# MAX32550 register map
Vendor: Maxim Integrated; File version: 1.0
Registers are 32-bit, read-write, reset 0x0 unless marked. A register's access mark holds for its fields unless they carry their own. Offsets are from the block's base; [hi:lo] are bit positions; {n}, {i} and the like mark numbered series.

## UART0 — UART0 (Serial Port 0)
Base 0x40020000; register names take the prefix UART0_
Same registers: UART1 0x40021000 (register names take the prefix UART1_)
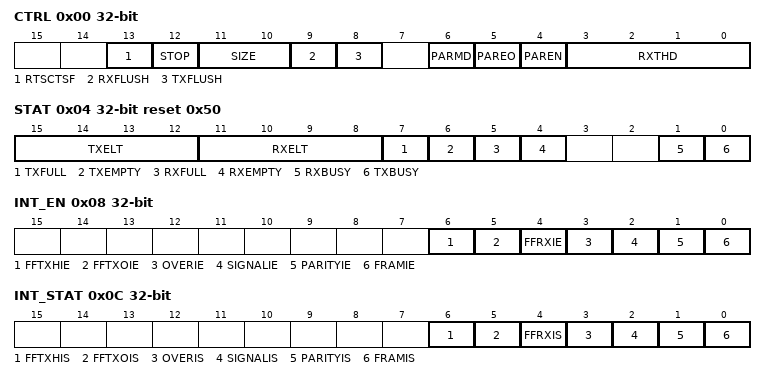
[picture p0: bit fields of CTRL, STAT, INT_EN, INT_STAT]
0x00 CTRL — UART Control Register
  [13] RTSCTSF — Enables/disables hardware flow control.
    0=disable; 1=enable
  [12] STOP — Selects the number of stop bits that will be generated.
    0=1 stop bit; 1=1.5 stop bits (for 5 bit mode) or 2 stop bits (for 6/7/8 bit mode)
  [11:10] SIZE — Selects UART character size.
    {v}=bits{v+5} (v=0..3)
  [9] RXFLUSH — Flushes the RX FIFO buffer.
    0=complete (No operation/complete); 1=Start operation
  [8] TXFLUSH — Flushes the TX FIFO buffer.
    0=complete (No operation/complete); 1=Start operation
  [6] PARMD — Selects parity based on 1s or 0s count (when PAREN=1).
    0=count1s (Parity calculation is based on number of 1s in frame.); 1=count0s (Parity calculation is based on number of 0s in frame.)
  [5] PAREO — Selects odd or even parity (when PAREN=1).
    0=even; 1=odd
  [4] PAREN — Enables/disables generation and testing of parity bit.
    0=disable; 1=enable
  [3:0] RXTHD — Number of bytes that must be loaded into the receive FIFO before the FFRXIS interrupt will be triggered.
    other=ignored; 1=bytes1 (Interrupt will be triggered when the number of bytes in the RX FIFO reaches 1 byte or higher.); {v}=bytes{v} (Interrupt will be triggered when the number of bytes in the RX FIFO reaches {v} bytes or higher.) (v=2..8)
0x04 STAT ro reset 0x50 — UART Status Register
  [15:12] TXELT — Indicates the number of bytes currently in the TX FIFO (0-8)
  [11:8] RXELT — Indicates the number of bytes currently in the RX FIFO (0-8)
  [7] TXFULL — Read-only flag indicating the TX FIFO state.
    0=notFull; 1=full
  [6] TXEMPTY — Read-only flag indicating the TX FIFO state.
    0=notEmpty; 1=empty
  [5] RXFULL — Read-only flag indicating the RX FIFO state.
    0=notFull; 1=full
  [4] RXEMPTY — Read-only flag indicating the RX FIFO state.
    0=notEmpty; 1=empty
  [1] RXBUSY — Read-only flag indicating the UART receiver status.
    0=idle; 1=busy
  [0] TXBUSY — Read-only flag indicating the UART transmit status.
    0=idle; 1=busy
0x08 INT_EN — UART Interrupt Enable Register
  [all] fields
    0=disable; 1=enable
  [6] FFTXHIE — Enable for interrupt when TX FIFO is half empty or less.
  [5] FFTXOIE — Enable for interrupt when TX FIFO has only one byte remaining.
  [4] FFRXIE — Enable for interrupt when RX FIFO reaches the number of bytes configured by the RXTHD field.
  [3] OVERIE — Enable for RX FIFO Overrun interrupt.
  [2] SIGNALIE — Enable for CTS signal change interrupt (hardware flow control disabled).
  [1] PARITYIE — Enable for RX Parity Error interrupt.
  [0] FRAMIE — Enable for RX Frame Error Interrupt.
0x0C INT_STAT — UART Interrupt Status Register
  [6] FFTXHIS write-0-clears — Flag for interrupt when TX FIFO is half empty or less.
  [5] FFTXOIS write-0-clears — Flag for interrupt when TX FIFO has only one byte remaining.
  [4] FFRXIS write-0-clears — Flag for interrupt when RX FIFO reaches the number of bytes configured by the RXTHD field.
  [3] OVERIS write-0-clears — Flag for RX FIFO Overrun interrupt.
  [2] SIGNALIS write-0-clears — Flag for CTS signal change interrupt (hardware flow control disabled).
  [1] PARITYIS write-0-clears — Flag for RX Parity Error interrupt.
  [0] FRAMIS write-0-clears — Flag for RX Frame Error Interrupt.
0x10 BAUD0 12-bit — UART Baud Rate 0 Register. Integer portion of baud rate divisor value. Use the following formula to obtain the proper value for this field: IDIV = (integer portion of) 'Nominal Frequency' / (128 x Baud Rate Frequency) where the 'Nominal Frequency' = 2xfPLL0. The integer portion is rounded value (i.e. 5.7 becomes 5).
0x14 BAUD1 7-bit — UART Baud Rate 1 Register. Decimal portion of baud rate divisor value. Use the following formula to obtain the proper value for this field after obtaining IDIV: DIV = 'Nominal Frequency' / (128 x Baud Rate Frequency). DDIV = (DIV - IDIV) x 128, where the 'Nominal Frequency' = 2xfPLL0.
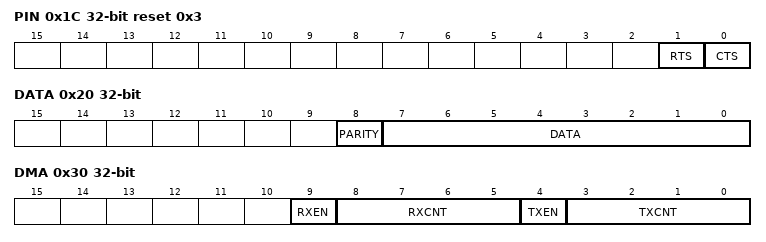
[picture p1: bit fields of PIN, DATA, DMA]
0x1C PIN reset 0x3 — UART Pin Control Register
  [1] RTS — If hardware flow control is disabled, this bit is used to control the RTS I/O pin output state. This bit has no effect when RTSCTSF=1.
    0=lo (Logic 0 (low)); 1=hi (Logic 1 (high))
  [0] CTS ro — Current state of CTS I/O pin.
    0=lo (Logic 0 (low)); 1=hi (Logic 1 (high))
0x20 DATA — UART Data Buffer Register
  [8] PARITY ro — Parity error flag for next byte to be read from FIFO.
    on read: 0=noError; 1=error
  [7:0] DATA — Load/unload location for TX and RX FIFO buffers.
0x30 DMA — UART DMA Register
  [9] RXEN — RX DMA channel enable
    0=disable; 1=enable
  [8:5] RXCNT — RX threshold for DMA transmission
  [4] TXEN — TX DMA channel enable
    0=disable; 1=enable
  [3:0] TXCNT — TX threshold for DMA transmission
